# PIC32CM5112GC00064 device description
Architecture: CORTEX-M23; Family: PIC32CM; Series: PIC32CMGC00
Registers are 32-bit, read-write, reset 0x0 unless marked. A register's access mark holds for its fields unless they carry their own. Offsets are from the block's base; [hi:lo] are bit positions; 'fields as' and 'values as' point back to an identical list.

## PTC — Polaris Peripheral Touch Controller
Instances: PTC 0x4482C000
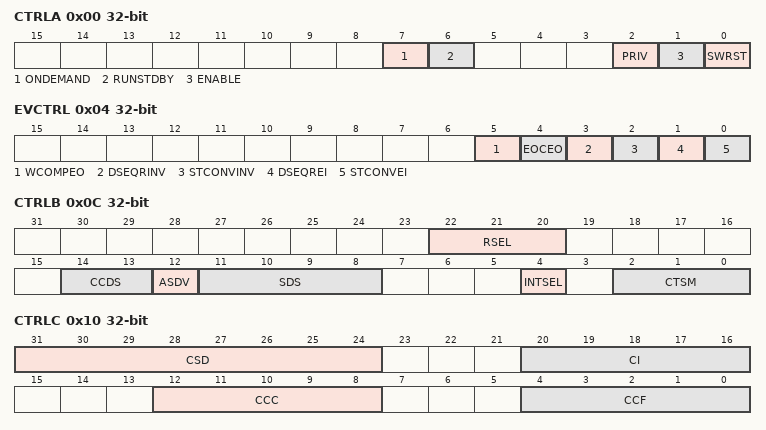
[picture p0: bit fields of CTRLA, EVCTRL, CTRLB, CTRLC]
0x00 CTRLA — CONTROL ENABLE REGISTER
  [7] ONDEMAND — On Demand Control
  [6] RUNSTDBY — Run In Standby
  [2] PRIV — Privileged Access Only -- provides filtering of privilege/non-privilege bus accesses to SFR registers
  [1] ENABLE — PTC -- Enable
    0=Disable module. System clock is only requested for bus transactions. GCLK is never requested.; 1=Enable module by allowing both the generic clock and system clock requests based on the incoming clock requests from the SIB
  [0] SWRST — Software Reset for this macro.
    0=There is no reset operation ongoing; 1=The reset operation is ongoing
0x04 EVCTRL — EVENT CONTROL REGISTER
  [5] WCOMPEO — Window Comparator Event Output Enable
  [4] EOCEO — End of Conversion Event Output Enable
  [3] DSEQRINV — DMA Sequencing Restart Event Invert Enable
  [2] STCONVINV — Start Conversion Event Invert Enable
  [1] DSEQREI — DMA Sequencing Restart Event Input Enable
  [0] STCONVEI — Start Conversion Event Input Enable
0x08 DBGCTRL — DEBUG CONTROL Register
  [0] DBGRUN — Debug Run
0x0C CTRLB (WSYNC) — CONTROL B Register
  [22:20] RSEL — Resistor Selection
  [14:13] CCDS — Channel Change Delay Selection
  [12] ASDV — Automatic Sampling Delay Variation.
  [11:8] SDS — Sampling Delay Selection.
  [4] INTSEL — Interrupt Selection
  [2:0] CTSM — Capacitive Touch Sensing Mode
0x10 CTRLC (WSYNC) — CONTROL C Register
  [31:24] CSD — Charge Share Delay Value
  [20:16] CI — Integration Capacitor Value
  [12:8] CCC — Compensation Capacitor Coarse Value
  [4:0] CCF — Compensation Capacitor Fine Value
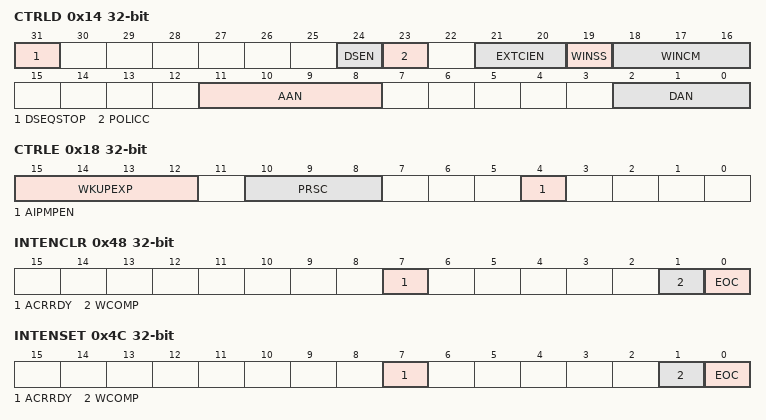
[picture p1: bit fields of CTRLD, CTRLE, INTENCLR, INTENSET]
0x14 CTRLD (WSYNC) — CONTROL D Register
  [31] DSEQSTOP — Stop DMA Sequence
  [24] DSEN — DSEN Driven Shield Enable.
  [23] POLICC — Polarity of Internal Compensation Capacitor
  [21:20] EXTCIEN — External Integration Capacitor Enable
  [19] WINSS — Window Single Sample
  [18:16] WINCM — Window Comparator Mode
  [11:8] AAN — Analog Accumulation Number
  [2:0] DAN — Digital Accumulation Number
0x18 CTRLE — CONTROL E REGISTER
  [15:12] WKUPEXP — Wake-Up Exponent
  [10:8] PRSC — This field defines the PTC clock relative to the peripheral clock according to the table below.
  [4] AIPMPEN — Analog Input Charge Pump Enable
0x1C SWTRIG (WSYNC) — Software Trigger Register
  [0] STCONV — Start Conversion
0x20 WINLT (WSYNC) — Window Comparator Low Threshold Register
  [15:0] WCLT — Window Comparator Low Threshold
0x24 WINHT (WSYNC) — Window Comparator High Threshold Register
  [15:0] WCHT — Window Comparator High Threshold
0x28 PINEN1 — PTC Line Enable 1 Register
  [31:0] PINEN — PTC-Line 31-0 Enable
0x2C PINEN2 — PTC Line Enable 2 Register
  [3:0] PINEN — PTC-Line 63-32 Enable
0x30 XSEL1 (WSYNC) — X Line Selection 1 Register
  [31:0] XSEL — X-Line Selection [31:0]
0x34 XSEL2 (WSYNC) — X Line Selection 2 Register
  [3:0] XSEL — X-Line Selection [63:32]
0x38 YSEL1 (WSYNC) — Y Line Selection 1 Register
  [31:0] YSEL — Y-Line Selection [31:0]
0x3C YSEL2 (WSYNC) — Y Line Selection 2 Register
  [3:0] YSEL — Y-Line Selection [63:32]
0x40 POLCTRL1 (WSYNC) — Polarity Control 1 Register
  [31:0] POLARITY — Choose X/Y lines Polarity [31:0]
0x44 POLCTRL2 (WSYNC) — Polarity Control 2 Register
  [3:0] POLARITY — Choose X/Y lines Polarity [63:32]
0x48 INTENCLR (atomic clear) — INTERRUPT ENABLE CLEAR Register
  [7] ACRRDY — Analog Core Ready Enable Clear.
  [1] WCOMP — Window Comparator Enable Clear.
  [0] EOC — End of Conversion Enable Clear.
0x4C INTENSET (atomic set) — INTERRUPT ENABLE SET Register
  [7] ACRRDY — Analog Core Ready Enable Set.
  [1] WCOMP — Window Comparator Enable Set.
  [0] EOC — End of Conversion Enable Set.
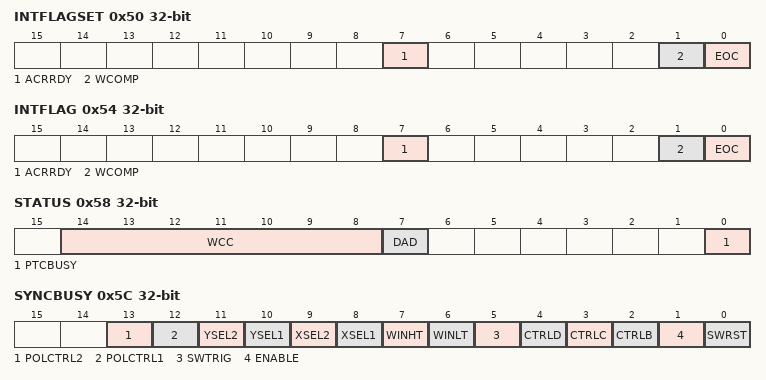
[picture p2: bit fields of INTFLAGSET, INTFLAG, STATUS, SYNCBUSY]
0x50 INTFLAGSET (atomic clear) — INTERRUPT FLAG SET Register
  fields as INTENSET
0x54 INTFLAG (atomic clear) — INTERRUPT FLAG STATUS and CLEAR Register
  [7] ACRRDY — Analog Core Ready Flag
  [1] WCOMP — Window Comparator Flag
  [0] EOC — End of Conversion Flag
0x58 STATUS ro
  [14:8] WCC — Window Comparator Counter
  [7] DAD — Digital Accumulation Done
  [0] PTCBUSY — PTC Busy Status
0x5C SYNCBUSY ro — Synchronization Register
  [13] POLCTRL2 — Polarity Control 2 Synchronization Busy
  [12] POLCTRL1 — Polarity Control 1 Synchronization Busy
  [11] YSEL2 — Y-lines Selection 2 Synchronization Busy
  [10] YSEL1 — Y-lines Selection 1 Synchronization Busy
  [9] XSEL2 — X-lines Selection 2 Synchronization Busy
  [8] XSEL1 — X-lines Selection 1 Synchronization Busy
  [7] WINHT — Window Comparator High Threshold Synchronization Busy
  [6] WINLT — Window Comparator Low Threshold Synchronization Busy
  [5] SWTRIG — Software Trigger Synchronization Busy
  [4] CTRLD — Control D Synchronization Busy
  [3] CTRLC — Control C Synchronization Busy
  [2] CTRLB — Control B Synchronization Busy
  [1] ENABLE — ENABLE Synchronization Busy
  [0] SWRST — SWRST Synchronization Busy --- Synchronizing Busy bit for swrst
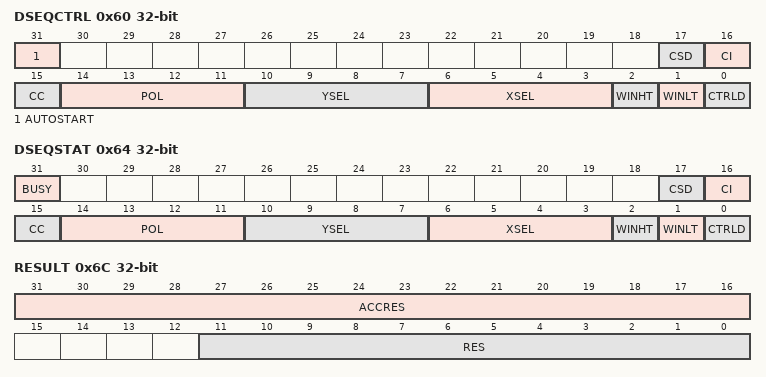
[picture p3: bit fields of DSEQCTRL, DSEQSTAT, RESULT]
0x60 DSEQCTRL — DMA SEQUENCE CTRL Register
  [31] AUTOSTART — PTC Auto-Start Conversion.
  [17] CSD — Charge Share Delay
  [16] CI — Integration Capacitor
  [15] CC — Compensation Capacitor
  [14:11] POL — Polarity n lower/upper half word
  [10:7] YSEL — Y-line n Selection lower/uper half word
  [6:3] XSEL — X-line n Selection lower/upper half word
  [2] WINHT — Window Comparator High Threshold
  [1] WINLT — Window Comparator Low Threshold
  [0] CTRLD — Control D.
0x64 DSEQSTAT ro — DMA SEQUENCE STATUS - Register
  [31] BUSY — Sequencing Busy
  [17] CSD — Charge Share Delay
  [16] CI — Integration Capacitor
  [15] CC — Compensation Capacitor
  [14:11] POL — Polarity n lower/upper half word
  [10:7] YSEL — Y-line n Selection lower/upper half word
  [6:3] XSEL — X-line n Selection lower/upper half word
  [2] WINHT — Window Comparator High Threshold
  [1] WINLT — Window Comparator Low Threshold
  [0] CTRLD — Control D.
0x68 DSEQDATA wo — DMA SEQUENCE DATA - Register
  [31:0] DATA — DMA Sequential Data.
0x6C RESULT ro — Register
  [31:16] ACCRES — Accumulated Result Conversion Value.
  [11:0] RES — Result Conversion Value.
